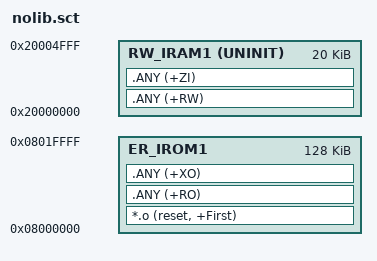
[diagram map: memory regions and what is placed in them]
; Разметка памяти

LR_IROM1 0x08000000 0x00020000  { ; Загрузочная область
  ER_IROM1 0x08000000 0x00020000  { ; Область исполняемого кода
   *.o (reset, +First) ; Первая секция, здесь располагается таблица векторов прерываний
   .ANY (+RO)
   .ANY (+XO)
  }
  RW_IRAM1 0x20000000 UNINIT 0x5000 { ; Область ОЗУ.
  ; UNINIT отключает первичную инициализацию данных, по этому стек и глобальные переменные
  ; при старте программы не будут обнуляться, и могут содержать мусор
   .ANY (+RW)
   .ANY (+ZI)
  }
}
